# ATSAM4LS2C register map
Vendor: Atmel Corporation; Series: SAM4L; File version: B
CPU: CM4 r0p1, little endian, MPU, no FPU, 4 interrupt priority bits
Registers are 32-bit, write-only, reset 0x0 unless marked. A register's access mark holds for its fields unless they carry their own. Offsets are from the block's base; [hi:lo] are bit positions; {n}, {i} and the like mark numbered series.

## GPIO — General-Purpose Input/Output Controller
Base 0x400E1000; register names take the prefix GPIO_
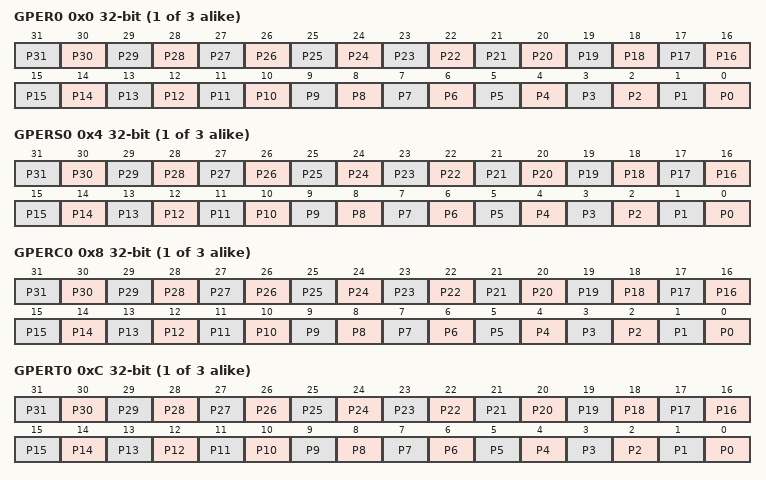
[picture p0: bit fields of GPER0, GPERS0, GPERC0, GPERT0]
{0x0+0x200*i} GPER{i} (i=0..2) rw — GPIO Enable Register
  [n] P{n} (n=0..31) — GPIO Enable
{0x4+0x200*i} GPERS{i} (i=0..2) — GPIO Enable Register - Set
  [n] P{n} (n=0..31) — GPIO Enable
{0x8+0x200*i} GPERC{i} (i=0..2) — GPIO Enable Register - Clear
  [n] P{n} (n=0..31) — GPIO Enable
{0xC+0x200*i} GPERT{i} (i=0..2) — GPIO Enable Register - Toggle
  [n] P{n} (n=0..31) — GPIO Enable
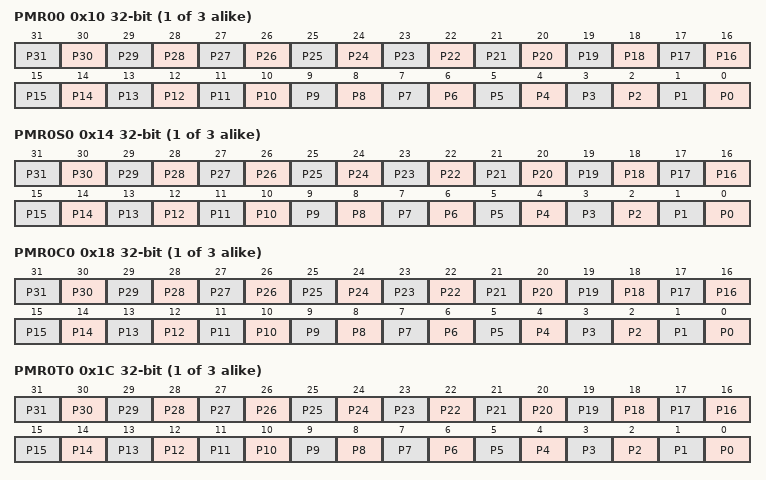
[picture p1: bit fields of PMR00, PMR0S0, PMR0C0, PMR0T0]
{0x10+0x200*i} PMR0{i} (i=0..2) rw — Peripheral Mux Register 0
  [n] P{n} (n=0..31) — Peripheral Multiplexer Select bit 0
{0x14+0x200*i} PMR0S{i} (i=0..2) — Peripheral Mux Register 0 - Set
  [n] P{n} (n=0..31) — Peripheral Multiplexer Select bit 0
{0x18+0x200*i} PMR0C{i} (i=0..2) — Peripheral Mux Register 0 - Clear
  [n] P{n} (n=0..31) — Peripheral Multiplexer Select bit 0
{0x1C+0x200*i} PMR0T{i} (i=0..2) — Peripheral Mux Register 0 - Toggle
  [n] P{n} (n=0..31) — Peripheral Multiplexer Select bit 0
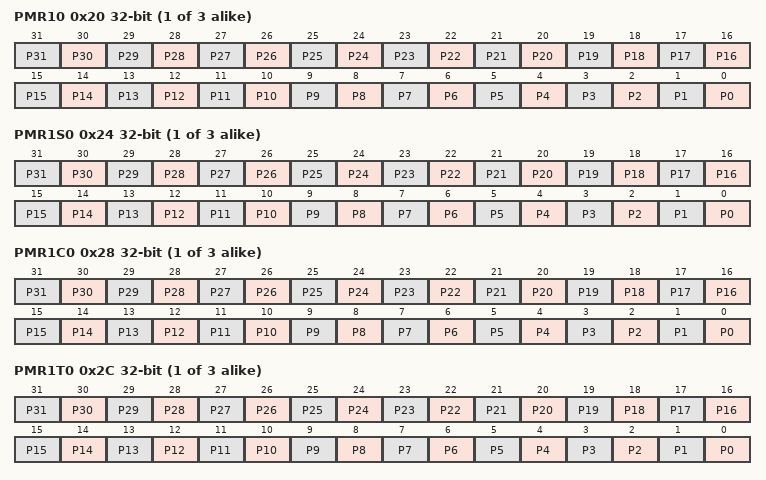
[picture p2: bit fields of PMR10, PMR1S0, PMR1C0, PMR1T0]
{0x20+0x200*i} PMR1{i} (i=0..2) rw — Peripheral Mux Register 1
  [n] P{n} (n=0..31) — Peripheral Multiplexer Select bit 1
{0x24+0x200*i} PMR1S{i} (i=0..2) — Peripheral Mux Register 1 - Set
  [n] P{n} (n=0..31) — Peripheral Multiplexer Select bit 1
{0x28+0x200*i} PMR1C{i} (i=0..2) — Peripheral Mux Register 1 - Clear
  [n] P{n} (n=0..31) — Peripheral Multiplexer Select bit 1
{0x2C+0x200*i} PMR1T{i} (i=0..2) — Peripheral Mux Register 1 - Toggle
  [n] P{n} (n=0..31) — Peripheral Multiplexer Select bit 1
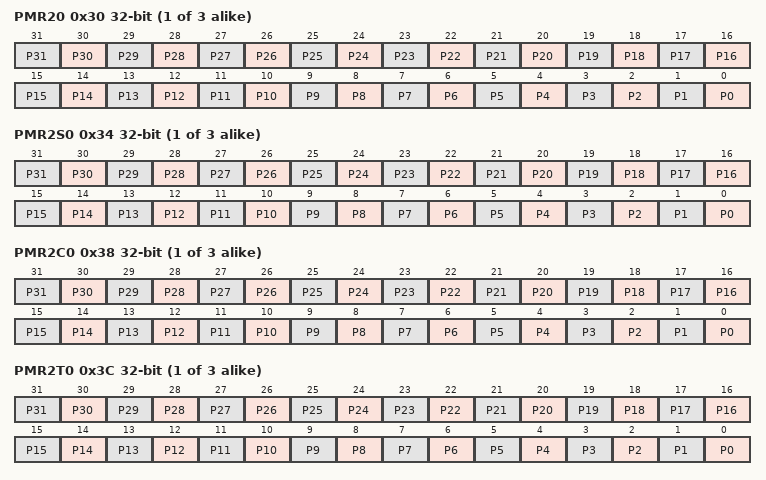
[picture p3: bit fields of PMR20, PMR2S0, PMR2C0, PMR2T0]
{0x30+0x200*i} PMR2{i} (i=0..2) rw — Peripheral Mux Register 2
  [n] P{n} (n=0..31) — Peripheral Multiplexer Select bit 2
{0x34+0x200*i} PMR2S{i} (i=0..2) — Peripheral Mux Register 2 - Set
  [n] P{n} (n=0..31) — Peripheral Multiplexer Select bit 2
{0x38+0x200*i} PMR2C{i} (i=0..2) — Peripheral Mux Register 2 - Clear
  [n] P{n} (n=0..31) — Peripheral Multiplexer Select bit 2
{0x3C+0x200*i} PMR2T{i} (i=0..2) — Peripheral Mux Register 2 - Toggle
  [n] P{n} (n=0..31) — Peripheral Multiplexer Select bit 2
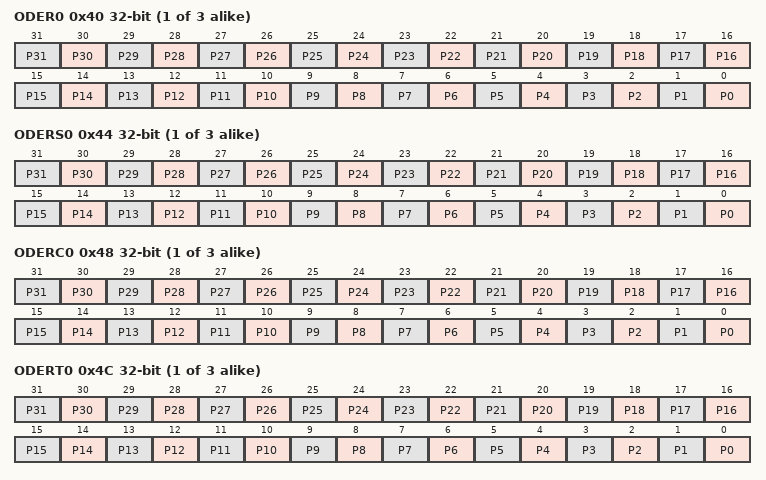
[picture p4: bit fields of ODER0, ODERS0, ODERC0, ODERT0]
{0x40+0x200*i} ODER{i} (i=0..2) rw — Output Driver Enable Register
  [n] P{n} (n=0..31) — Output Driver Enable
{0x44+0x200*i} ODERS{i} (i=0..2) — Output Driver Enable Register - Set
  [n] P{n} (n=0..31) — Output Driver Enable
{0x48+0x200*i} ODERC{i} (i=0..2) — Output Driver Enable Register - Clear
  [n] P{n} (n=0..31) — Output Driver Enable
{0x4C+0x200*i} ODERT{i} (i=0..2) — Output Driver Enable Register - Toggle
  [n] P{n} (n=0..31) — Output Driver Enable
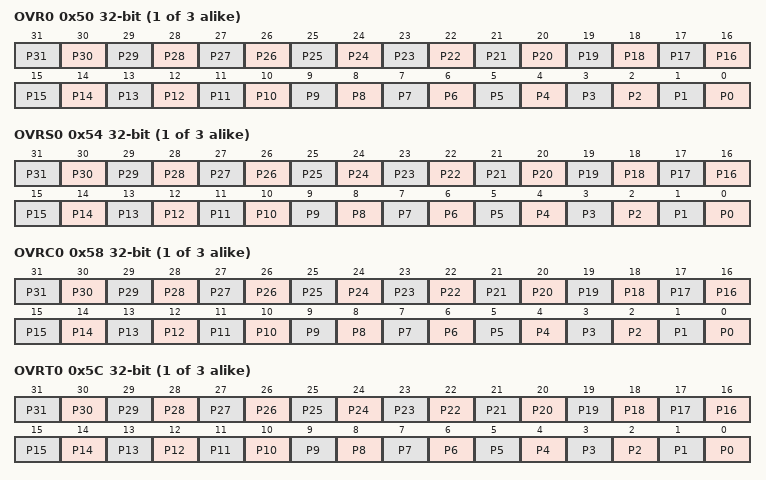
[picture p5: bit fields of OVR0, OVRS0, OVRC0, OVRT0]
{0x50+0x200*i} OVR{i} (i=0..2) rw — Output Value Register
  [n] P{n} (n=0..31) — Output Value
{0x54+0x200*i} OVRS{i} (i=0..2) — Output Value Register - Set
  [n] P{n} (n=0..31) — Output Value
{0x58+0x200*i} OVRC{i} (i=0..2) — Output Value Register - Clear
  [n] P{n} (n=0..31) — Output Value
{0x5C+0x200*i} OVRT{i} (i=0..2) — Output Value Register - Toggle
  [n] P{n} (n=0..31) — Output Value
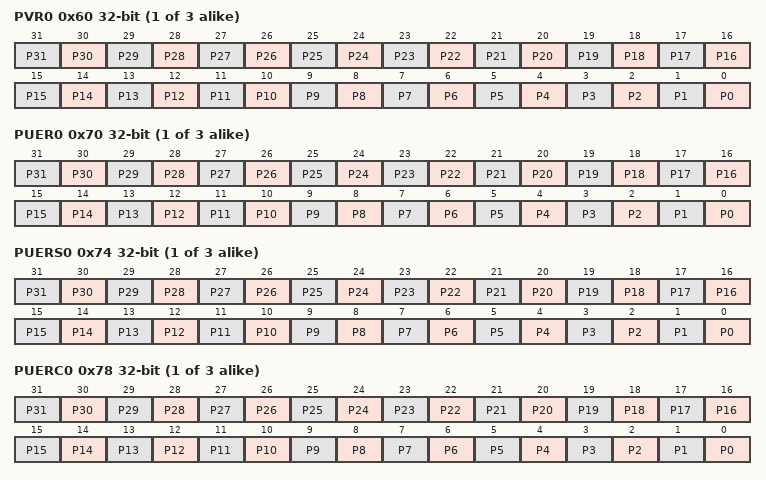
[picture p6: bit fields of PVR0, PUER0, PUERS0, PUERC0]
{0x60+0x200*i} PVR{i} (i=0..2) ro — Pin Value Register
  [n] P{n} (n=0..31) — Pin Value
{0x70+0x200*i} PUER{i} (i=0..2) rw — Pull-up Enable Register
  [n] P{n} (n=0..31) — Pull-up Enable
{0x74+0x200*i} PUERS{i} (i=0..2) — Pull-up Enable Register - Set
  [n] P{n} (n=0..31) — Pull-up Enable
{0x78+0x200*i} PUERC{i} (i=0..2) — Pull-up Enable Register - Clear
  [n] P{n} (n=0..31) — Pull-up Enable
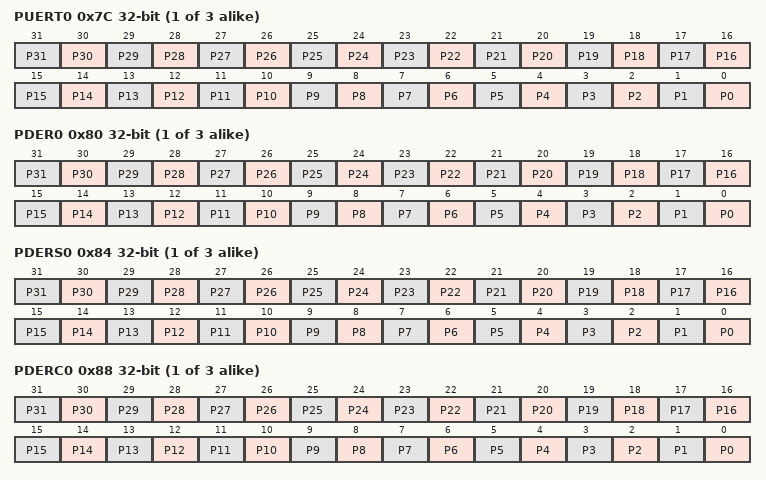
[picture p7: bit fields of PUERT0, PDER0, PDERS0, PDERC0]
{0x7C+0x200*i} PUERT{i} (i=0..2) — Pull-up Enable Register - Toggle
  [n] P{n} (n=0..31) — Pull-up Enable
{0x80+0x200*i} PDER{i} (i=0..2) rw — Pull-down Enable Register
  [n] P{n} (n=0..31) — Pull-down Enable
{0x84+0x200*i} PDERS{i} (i=0..2) — Pull-down Enable Register - Set
  [n] P{n} (n=0..31) — Pull-down Enable
{0x88+0x200*i} PDERC{i} (i=0..2) — Pull-down Enable Register - Clear
  [n] P{n} (n=0..31) — Pull-down Enable
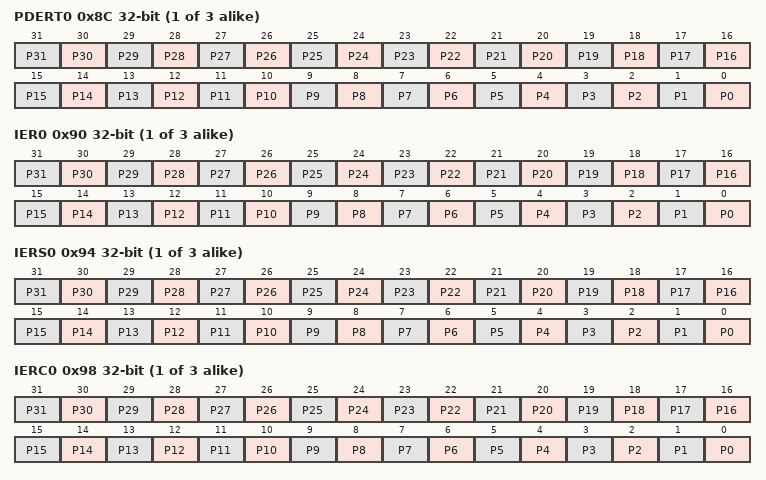
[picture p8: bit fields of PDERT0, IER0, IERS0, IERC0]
{0x8C+0x200*i} PDERT{i} (i=0..2) — Pull-down Enable Register - Toggle
  [n] P{n} (n=0..31) — Pull-down Enable
{0x90+0x200*i} IER{i} (i=0..2) rw — Interrupt Enable Register
  [n] P{n} (n=0..31) — Interrupt Enable
{0x94+0x200*i} IERS{i} (i=0..2) — Interrupt Enable Register - Set
  [n] P{n} (n=0..31) — Interrupt Enable
{0x98+0x200*i} IERC{i} (i=0..2) — Interrupt Enable Register - Clear
  [n] P{n} (n=0..31) — Interrupt Enable
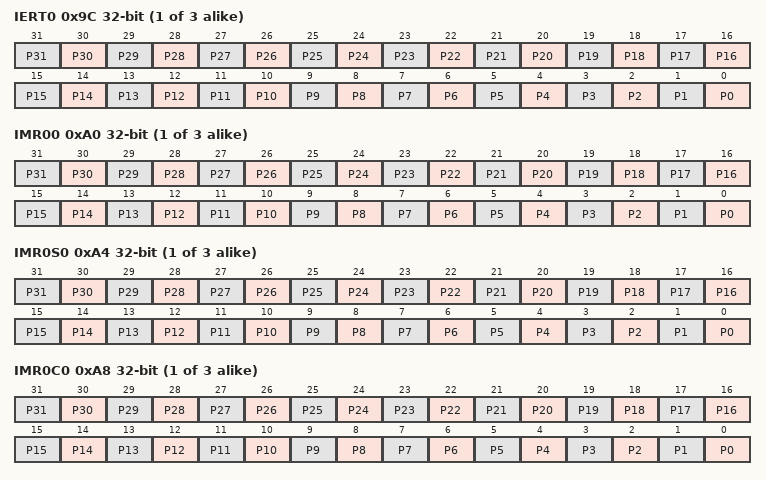
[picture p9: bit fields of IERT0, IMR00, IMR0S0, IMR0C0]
{0x9C+0x200*i} IERT{i} (i=0..2) — Interrupt Enable Register - Toggle
  [n] P{n} (n=0..31) — Interrupt Enable
{0xA0+0x200*i} IMR0{i} (i=0..2) rw — Interrupt Mode Register 0
  [n] P{n} (n=0..31) — Interrupt Mode Bit 0
{0xA4+0x200*i} IMR0S{i} (i=0..2) — Interrupt Mode Register 0 - Set
  [n] P{n} (n=0..31) — Interrupt Mode Bit 0
{0xA8+0x200*i} IMR0C{i} (i=0..2) — Interrupt Mode Register 0 - Clear
  [n] P{n} (n=0..31) — Interrupt Mode Bit 0
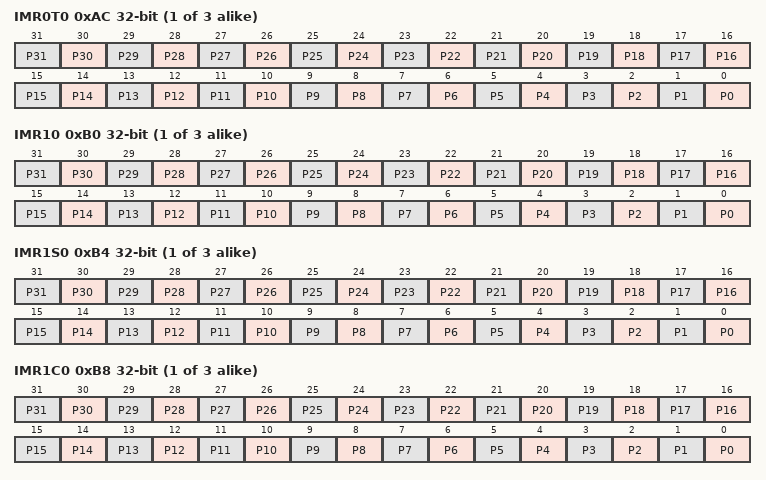
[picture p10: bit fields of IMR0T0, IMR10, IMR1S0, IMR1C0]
{0xAC+0x200*i} IMR0T{i} (i=0..2) — Interrupt Mode Register 0 - Toggle
  [n] P{n} (n=0..31) — Interrupt Mode Bit 0
{0xB0+0x200*i} IMR1{i} (i=0..2) rw — Interrupt Mode Register 1
  [n] P{n} (n=0..31) — Interrupt Mode Bit 1
{0xB4+0x200*i} IMR1S{i} (i=0..2) — Interrupt Mode Register 1 - Set
  [n] P{n} (n=0..31) — Interrupt Mode Bit 1
{0xB8+0x200*i} IMR1C{i} (i=0..2) — Interrupt Mode Register 1 - Clear
  [n] P{n} (n=0..31) — Interrupt Mode Bit 1
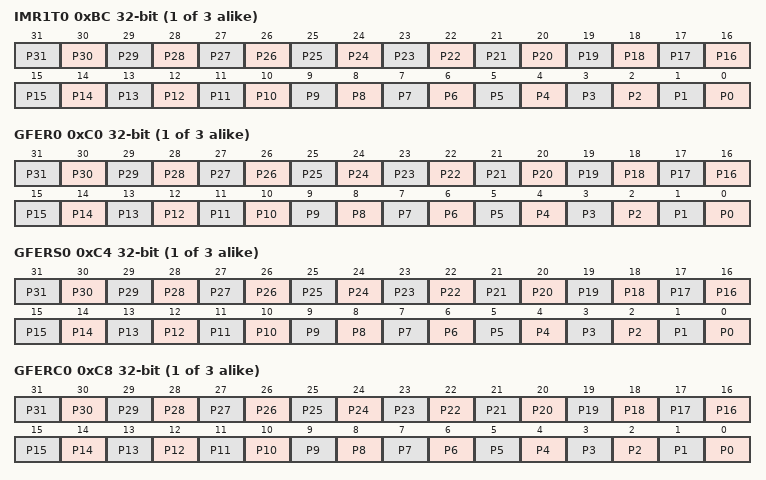
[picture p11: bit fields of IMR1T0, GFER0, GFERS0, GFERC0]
{0xBC+0x200*i} IMR1T{i} (i=0..2) — Interrupt Mode Register 1 - Toggle
  [n] P{n} (n=0..31) — Interrupt Mode Bit 1
{0xC0+0x200*i} GFER{i} (i=0..2) rw — Glitch Filter Enable Register
  [n] P{n} (n=0..31) — Glitch Filter Enable
{0xC4+0x200*i} GFERS{i} (i=0..2) — Glitch Filter Enable Register - Set
  [n] P{n} (n=0..31) — Glitch Filter Enable
{0xC8+0x200*i} GFERC{i} (i=0..2) — Glitch Filter Enable Register - Clear
  [n] P{n} (n=0..31) — Glitch Filter Enable
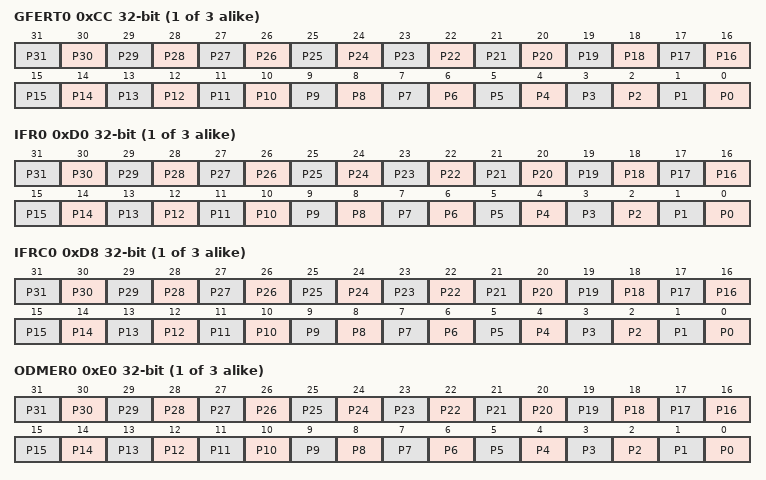
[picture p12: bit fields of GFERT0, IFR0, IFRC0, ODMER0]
{0xCC+0x200*i} GFERT{i} (i=0..2) — Glitch Filter Enable Register - Toggle
  [n] P{n} (n=0..31) — Glitch Filter Enable
{0xD0+0x200*i} IFR{i} (i=0..2) ro — Interrupt Flag Register
  [n] P{n} (n=0..31) — Interrupt Flag
{0xD8+0x200*i} IFRC{i} (i=0..2) — Interrupt Flag Register - Clear
  [n] P{n} (n=0..31) — Interrupt Flag
{0xE0+0x200*i} ODMER{i} (i=0..2) rw — Open Drain Mode Register
  [n] P{n} (n=0..31) — Open Drain Mode Enable
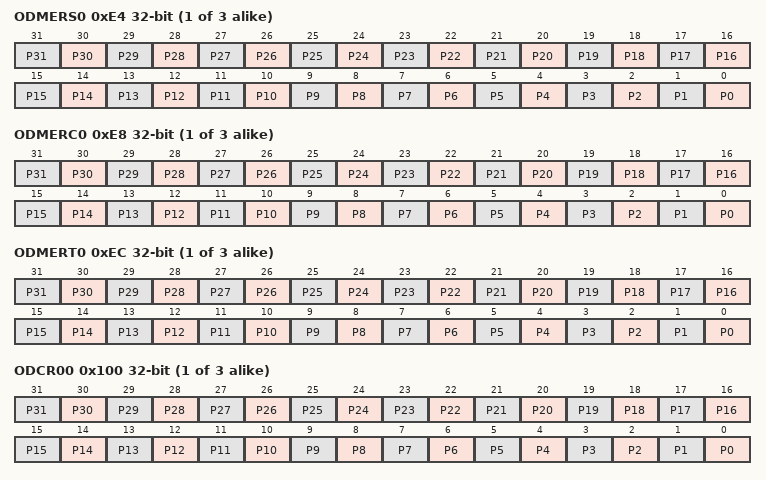
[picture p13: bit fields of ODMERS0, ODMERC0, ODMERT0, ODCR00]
{0xE4+0x200*i} ODMERS{i} (i=0..2) — Open Drain Mode Register - Set
  [n] P{n} (n=0..31) — Open Drain Mode Enable
{0xE8+0x200*i} ODMERC{i} (i=0..2) — Open Drain Mode Register - Clear
  [n] P{n} (n=0..31) — Open Drain Mode Enable
{0xEC+0x200*i} ODMERT{i} (i=0..2) — Open Drain Mode Register - Toggle
  [n] P{n} (n=0..31) — Open Drain Mode Enable
{0x100+0x200*i} ODCR0{i} (i=0..2) rw — Output Driving Capability Register 0
  [n] P{n} (n=0..31) — Output Driving Capability Register Bit 0
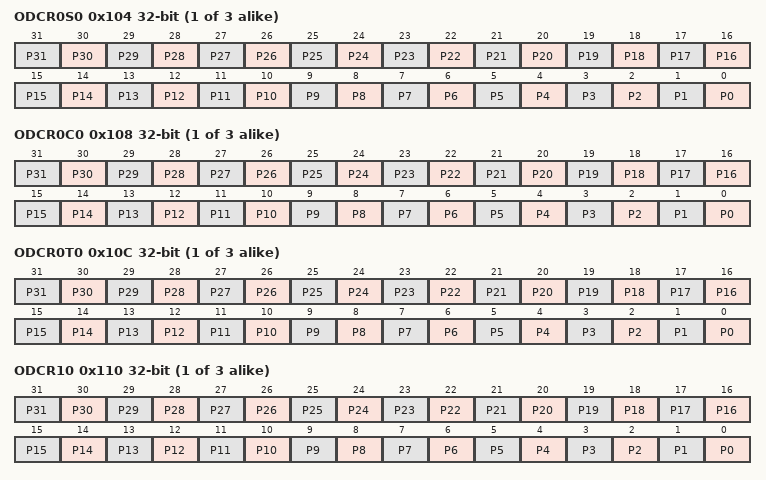
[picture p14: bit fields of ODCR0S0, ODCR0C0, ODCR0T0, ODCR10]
{0x104+0x200*i} ODCR0S{i} (i=0..2) rw — Output Driving Capability Register 0 - Set
  [n] P{n} (n=0..31) — Output Driving Capability Register Bit 0
{0x108+0x200*i} ODCR0C{i} (i=0..2) rw — Output Driving Capability Register 0 - Clear
  [n] P{n} (n=0..31) — Output Driving Capability Register Bit 0
{0x10C+0x200*i} ODCR0T{i} (i=0..2) rw — Output Driving Capability Register 0 - Toggle
  [n] P{n} (n=0..31) — Output Driving Capability Register Bit 0
{0x110+0x200*i} ODCR1{i} (i=0..2) rw — Output Driving Capability Register 1
  [n] P{n} (n=0..31) — Output Driving Capability Register Bit 1
{0x114+0x200*i} ODCR1S{i} (i=0..2) rw — Output Driving Capability Register 1 - Set
  [n] P{n} (n=0..31) — Output Driving Capability Register Bit 1
{0x118+0x200*i} ODCR1C{i} (i=0..2) rw — Output Driving Capability Register 1 - Clear
  [n] P{n} (n=0..31) — Output Driving Capability Register Bit 1
{0x11C+0x200*i} ODCR1T{i} (i=0..2) rw — Output Driving Capability Register 1 - Toggle
  [n] P{n} (n=0..31) — Output Driving Capability Register Bit 1
{0x130+0x200*i} OSRR0{i} (i=0..2) rw — Output Slew Rate Register 0
  [n] P{n} (n=0..31) — Output Slew Rate Control Enable
{0x134+0x200*i} OSRR0S{i} (i=0..2) rw — Output Slew Rate Register 0 - Set
  [n] P{n} (n=0..31) — Output Slew Rate Control Enable
{0x138+0x200*i} OSRR0C{i} (i=0..2) rw — Output Slew Rate Register 0 - Clear
  [n] P{n} (n=0..31) — Output Slew Rate Control Enable
{0x13C+0x200*i} OSRR0T{i} (i=0..2) rw — Output Slew Rate Register 0 - Toggle
  [n] P{n} (n=0..31) — Output Slew Rate Control Enable
{0x160+0x200*i} STER{i} (i=0..2) rw — Schmitt Trigger Enable Register
  [n] P{n} (n=0..31) — Schmitt Trigger Enable
{0x164+0x200*i} STERS{i} (i=0..2) rw — Schmitt Trigger Enable Register - Set
  [n] P{n} (n=0..31) — Schmitt Trigger Enable
{0x168+0x200*i} STERC{i} (i=0..2) rw — Schmitt Trigger Enable Register - Clear
  [n] P{n} (n=0..31) — Schmitt Trigger Enable
{0x16C+0x200*i} STERT{i} (i=0..2) rw — Schmitt Trigger Enable Register - Toggle
  [n] P{n} (n=0..31) — Schmitt Trigger Enable
{0x180+0x200*i} EVER{i} (i=0..2) rw — Event Enable Register
  [n] P{n} (n=0..31) — Event Enable
{0x184+0x200*i} EVERS{i} (i=0..2) — Event Enable Register - Set
  [n] P{n} (n=0..31) — Event Enable
{0x188+0x200*i} EVERC{i} (i=0..2) — Event Enable Register - Clear
  [n] P{n} (n=0..31) — Event Enable
{0x18C+0x200*i} EVERT{i} (i=0..2) — Event Enable Register - Toggle
  [n] P{n} (n=0..31) — Event Enable
{0x1A0+0x200*i} LOCK{i} (i=0..2) rw
  [n] P{n} (n=0..31) — Lock State
{0x1A4+0x200*i} LOCKS{i} (i=0..2) — Lock Register - Set
  [n] P{n} (n=0..31) — Lock State
{0x1A8+0x200*i} LOCKC{i} (i=0..2) — Lock Register - Clear
  [n] P{n} (n=0..31) — Lock State
{0x1AC+0x200*i} LOCKT{i} (i=0..2) — Lock Register - Toggle
  [n] P{n} (n=0..31) — Lock State
{0x1E0+0x200*i} UNLOCK{i} (i=0..2)
  [31:24] KEY — Unlocking Key
  [9:0] ADDR — Offset Register
{0x1E4+0x200*i} ASR{i} (i=0..2) rw — Access Status Register
  [0] AR — Access Error
{0x1F8+0x200*i} PARAMETER{i} (i=0..2) ro
  [31:0] PARAMETER
{0x1FC+0x200*i} VERSION{i} (i=0..2) ro reset 0x215
  [19:16] VARIANT — Variant Number
  [11:0] VERSION — Version Number

## Notices in the file
Atmel Microcontroller Software Support
Copyright (c) 2014, Atmel Corporation
All rights reserved.
Redistribution and use in source and binary forms, with or without
modification, are permitted provided that the following condition is met:
- Redistributions of source code must retain the above copyright notice,
this list of conditions and the disclaimer below.
Atmel's name may not be used to endorse or promote products derived from
this software without specific prior written permission.
DISCLAIMER: THIS SOFTWARE IS PROVIDED BY ATMEL "AS IS" AND ANY EXPRESS OR
IMPLIED WARRANTIES, INCLUDING, BUT NOT LIMITED TO, THE IMPLIED WARRANTIES OF
MERCHANTABILITY, FITNESS FOR A PARTICULAR PURPOSE AND NON-INFRINGEMENT ARE
DISCLAIMED. IN NO EVENT SHALL ATMEL BE LIABLE FOR ANY DIRECT, INDIRECT,
INCIDENTAL, SPECIAL, EXEMPLARY, OR CONSEQUENTIAL DAMAGES (INCLUDING, BUT NOT
LIMITED TO, PROCUREMENT OF SUBSTITUTE GOODS OR SERVICES; LOSS OF USE, DATA,
OR PROFITS; OR BUSINESS INTERRUPTION) HOWEVER CAUSED AND ON ANY THEORY OF
LIABILITY, WHETHER IN CONTRACT, STRICT LIABILITY, OR TORT (INCLUDING
NEGLIGENCE OR OTHERWISE) ARISING IN ANY WAY OUT OF THE USE OF THIS SOFTWARE,
EVEN IF ADVISED OF THE POSSIBILITY OF SUCH DAMAGE.
